# rCSL_mmcsd_001 register map
Vendor: Texas Instruments
Peripheral module from a debugger description file (folder OMAPL138_C6748).
Registers are 32-bit, access not given, reset 0x0 unless marked. A register's access mark holds for its fields unless they carry their own. Offsets are as the file gives them; lines under a group give offsets from that group; [hi:lo] are bit positions; {n}, {i} and the like mark numbered series; 'fields as' and 'values as' point back to an identical list; <NAME> marks a mode.

## MMCSD — MMC/SD Controller
0x00 MMCCTL — MMC Control Register
  [10] PERMDX rw — Endian select Enable when writing
    0=LEND (Little Endian is selected); 1=BEND (Big Endian is selected)
  [9] PERMDR rw — Endian select Enable when reading
    values as PERMDX
  [8] WIDTH1 rw — Data Bus Width1 (in only MMC mode)
  [8] WIDTH0 rw — Data Bus Width0 (in only MMC mode)
  [7:6] DATEG rw — DAT3 Edge Detection Select
  [1] CMDRST rw — CMD Logic Reset
    0=ENABLE (The CMD line portion is enabled); 1=DISABLE (The CMD line portion is disabled and in reset state)
  [0] DATRST rw — DAT Logic Reset
    0=ENABLE (The DAT line portion is enabled); 1=DISABLE (The DAT line portion is disabled and in reset state)
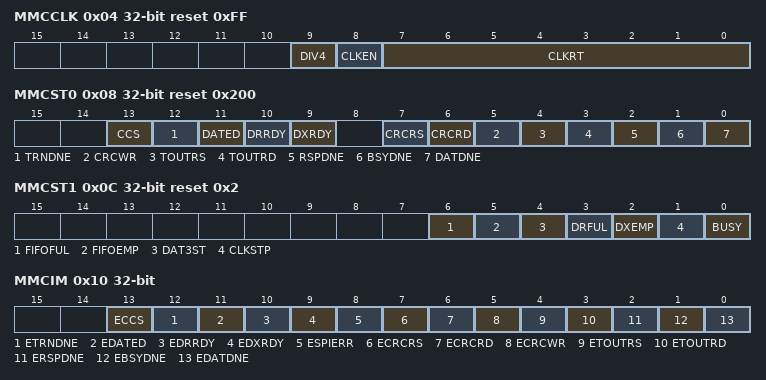
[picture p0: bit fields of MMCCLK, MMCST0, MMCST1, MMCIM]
0x04 MMCCLK reset 0xFF — MMC Memory Clock Register
  [9] DIV4 rw — DIV4 option
    0=DISABLE (DIV4 is disabled); 1=ENABLE (DIV4 is enabled)
  [8] CLKEN rw — CLK Enable
    0=DISABLE (CLK pin is disabled and fixed); 1=ENABLE (CLK pin is enabled)
  [7:0] CLKRT rw — Clock Pin Rate&#10;This indicates divider rate of the function clock&#10;MMC clock = function clock /2*(ClockRate + 1)
0x08 MMCST0 reset 0x200 — MMC Status Register 0
  [13] CCS ro — Command Completion Signal &#10;0: Command 61 is not completed&#10;1: Command 61 is completed
    0=Not_completed (Command 61 not completed); 1=Completed (Command 61 completed)
  [12] TRNDNE ro — Transfer Done&#10;0: No data transfer is done&#10;1:Data transfer of specified length is done
    0=Not_done (Data transfer not done); 1=Done (Data transfer done)
  [11] DATED ro — DAT3 Edge Detect, bit is cleared when read by CPU&#10;0: No DAT3 edge is detected&#10;1: DAT3 edge has been detected
    0=Not_detected (DAT3 Edge not detected); 1=Detected (DAT3 Edge detected)
  [10] DRRDY ro — Data Receive Ready&#10;0: MMCDRR is not ready&#10;1: MMCDRR is ready to be reading a newdata by CPU or DMA
    0=Not_ready (DRR not ready); 1=Ready (DRR ready)
  [9] DXRDY ro — Data Transmit Ready&#10;0: MMCDXR is not ready&#10;1: MMCDXR is ready to be writing a new data by CPU or DMA
    0=Not_ready (DXR not ready); 1=Ready (DXR ready)
  [7] CRCRS ro — CRC error (response)&#10;0: No CRC error is detected&#10;1: CRC error has been detected
    0=Not_detected (CRC response not detected); 1=Detected (CRC response detected)
  [6] CRCRD ro — CRC error (read data)&#10;0: No CRC error is detected&#10;1: CRC error has been detected
    0=Not_detected (CRC read data not detected); 1=Detected (CRC read data detected)
  [5] CRCWR ro — CRC error (write data)&#10;0: No CRC error is detected&#10;1: CRC error has been detected
    0=Not_detected (CRC write data not detected); 1=Detected (CRC write data detected)
  [4] TOUTRS ro — Time_Out (response)&#10;0: No time_out occurs&#10;1: Time_out has occurred during waiting response
    0=Not_occurred (Time-Out response not occurred); 1=Occurred (Time-Out response occurred)
  [3] TOUTRD ro — Time_Out (read data)&#10;0: No time_out occurs&#10;1: Time_out has occurred during waiting response
    0=Not_occurred (Time-Out read data not occurred); 1=Occurred (Time-Out read data occurred)
  [2] RSPDNE ro — Command / Response Done&#10;0: No Receiving response done&#10;1: Response successfully has received or command has sent without response
    0=Not_received (Command/Response not received); 1=Received (Command/Response received)
  [1] BSYDNE ro — Busy Done&#10;0: No busy releasing done&#10;1: Released from busy state or expected busy not detected
    0=Not_released (Busy state not released); 1=Released (Busy state released)
  [0] DATDNE ro — Data Done&#10;0: No data transfer done&#10;1: Data transfer of specified length successfully done
    values as TRNDNE
0x0C MMCST1 reset 0x2 — MMC Status Register 1
  [6] FIFOFUL ro — FIFO is full&#10;0: FIFO is not full&#10;1: FIFO is full
    0=Not_full (FIFO not full); 1=Full (FIFO full)
  [5] FIFOEMP ro — FIFO contains no data&#10;0: FIFO is not empty&#10;1: FIFO is empty
    0=Not_empty (FIFO not empty); 1=Empty (FIFO empty)
  [4] DAT3ST ro — DAT3 Status&#10;0: The status of DAT3 is L level&#10;1: The status of DAT3 is H level
    0=Low (DAT3 status low); 1=High (DAT3 status high)
  [3] DRFUL ro — DRRDY Data receive full&#10;0: MMCDRR(data receive register) is not full&#10;1: MMCDRR(data receive register) is full
    0=Not_full (DRR not full); 1=Full (DRR full)
  [2] DXEMP ro — DXRDY Data transmit empty&#10;0: MMCDXR(data transmit register) is not empty&#10;1: MMCDXR(data transmit register) is empty
    0=Not_empty (DXR not empty); 1=Empty (DXR empty)
  [1] CLKSTP ro — Clock Stop Status&#10;0:CLK is active&#10;1:CLK is held L because of no sending data during CLKEN is 0, receive shift register is full, transmit shift register is empty
    0=Low (Clock Stop status low); 1=High (Clock Stop status high)
  [0] BUSY ro — Busy&#10;0: No busy signal is detected&#10;1: Busy signal is detected after response with busy or during block write
    0=Not_detected (Busy not detected); 1=Detected (Busy detected)
0x10 MMCIM — MMC Interrupt Mask Register
  [all] fields
    0=PROHIBIT; 1=PERMIT
  [13] ECCS rw — CCS permission bit
  [12] ETRNDNE rw — TRNDNE permission bit
  [11] EDATED rw — DATED permission bit
  [10] EDRRDY rw — DRRDY permission bit
  [9] EDXRDY rw — DXRDY permission bit
  [8] ESPIERR rw — SPIERR permission bit (in SPI mode)
  [7] ECRCRS rw — CRCRS permission bit (response)
  [6] ECRCRD rw — CRCRD permission bit (read data)
  [5] ECRCWR rw — CRCWR permission bit (write data)
  [4] ETOUTRS rw — TOUTRS permission bit (response)
  [3] ETOUTRD rw — TOUTRD permission bit (read data)
  [2] ERSPDNE rw — RSPDNE permission bit
  [1] EBSYDNE rw — BSYDNE permission bit
  [0] EDATDNE rw — DATDNE permission bit
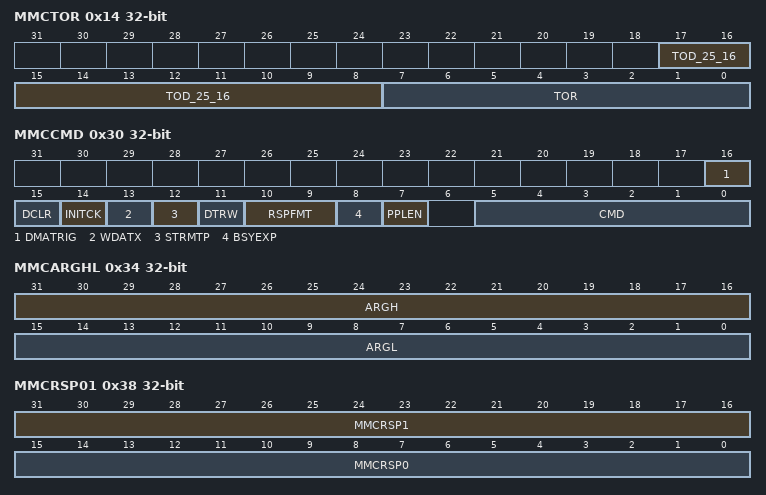
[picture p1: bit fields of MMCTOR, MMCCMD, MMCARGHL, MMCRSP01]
0x14 MMCTOR — MMC Response Time-out Register
  [17:8] TOD_25_16 rw — Upper 10 bit of Data TimeOut Register (in MMC and SPI Modes)&#10;Time_Out Count For Data Read (in MMC mode)&#10; 0x00000: no time_out&#10; 0x00001: 1 CLK clock&#10; 0x00002: 2 CLK clocks&#10; ...&#10; 0x1FFFF: 2097151 CLK clocks&#10;Time_Out Count For Data Read (in SPI mode)&#10; 0x00000: no time_out&#10; 0x00001: 1 x 8 CLK clocks&#10; 0x00002: 2 x 8 CLK clocks&#10; ...&#10; 0x1FFFFF: 2097151 x 8 CLK clocks
  [7:0] TOR rw — Time_Out Count For Response&#10;In MMC mode&#10; 0000 0000: no time_out&#10; 0000 0001: 1 CLK clock&#10; 0000 0010: 2 CLK clocks &#10; ...&#10; 1111 1111: 255 CLK clocks&#10;In SPI mode&#10; 0000 0000: no time_out&#10; 0000 0001: 1 x 8 CLK clock&#10; 0000 0010: 2 x 8 CLK clocks &#10; ...&#10; 1111 1111: 255 x 8 CLK clocks
0x18 MMCTOD — MMC Data Read Time-out Register
  [15:0] TOD_15_0 rw — Lower 16 bit of Data TimeOut Register&#10;Time_Out Count For Data Read (in MMC mode)&#10; 0x00000: no time_out&#10; 0x00001: 1 CLK clock&#10; 0x00002: 2 CLK clocks&#10; ...&#10; 0x1FFFF: 2097151 CLK clocks&#10;Time_Out Count For Data Read (in SPI mode)&#10; 0x00000: no time_out&#10; 0x00001: 1 x 8 CLK clocks&#10; 0x00002: 2 x 8 CLK clocks&#10; ...&#10; 0x1FFFFF: 2097151 x 8 CLK clocks
0x1C MMCBLEN reset 0x200 — MMC Block Length Register
  [11:0] BLEN rw — Block Length&#10;Specifies the byte count of a data block. Value 0x000 is prohibited
0x20 MMCNBLK — MMC Number of Blocks Register
  [15:0] NBLK rw — Number of Blocks&#10;Specifies the total number of blocks to be transferred.The value 0x0000 means infinite blocks
0x24 MMCNBLC reset 0xFFFF — MMC Number of Blocks Counter
  [15:0] NBLC rw — MMCNBLC is used in order to test the counter which operates with the value of MMCNBLK in a factory test or a chip evaluation&#10;Reading is possible in order to check the number of blocks to be transferred But Writing to this register is prohibited by User
0x28 MMCDRR rw — MMC Data Receive Register
  [31:0] DRR — This register is used for reading of receive data from card when block read&#10;&#10;Register expects little endian formatting
0x2C MMCDXR rw — MMC Data Transmit Register
  [31:0] DXR — This register is used for writing of transmit data to card when block write&#10;&#10;Register expects little endian formatting
0x30 MMCCMD — MMC Command Register
  [16] DMATRIG rw — DMA transfer event generation enable
    0=NO (Do not generate DMA transfer event); 1=YES (Generate DMA transfer event (mmcsd_dma_xready_o))
  [15] DCLR rw — Data Receive/Transmit Clear
    0=NO (No clear); 1=CLEAR
  [14] INITCK rw — Initialize Clock&#10;Before sending the command (specified in CMD), 80 cycles of dummy clock will be inserted. This is required for resetting a card after power_on
    0=NO (No initialization clock); 1=INIT (Initialization clock insertion)
  [13] WDATX rw — With Data
    0=NO (No data transfer); 1=DATA (With data transfer)
  [12] STRMTP rw — Stream Transfer
    0=BLOCK (Block data transfer); 1=STREAM (Stream data transfer); 0=NO (When WDATX = 0)
  [11] DTRW rw — Write
    0=READ (Data read); 1=WRITE (Data write); 0=NO (When WDATX = 0)
  [10:9] RSPFMT rw — Response Format&#10;00:&#10;01: R1/R4/R5/R6 (48_bit length)&#10;10: R2 (136_bit length)&#10;11: R3 (48_bit length, without CRC)
  [8] BSYEXP rw — Busy Expected
    0=NO (No busy signal expected); 1=BUSY (Busy signal expected or in case of transfer abort)
  [7] PPLEN rw — Push Pull Enable
    0=OD (Push Pull Driver of CMD line is disable (Open drain)); 1=PP (Push Pull Driver of CMD line is enable)
  [5:0] CMD rw — Command Index&#10;The command to be sent to the CMD line
0x34 MMCARGHL rw — MMC Argument Register
  [31:16] ARGH — MSB of Argument Register&#10;MMCARGHL is used for specifying the arguments to be sent with the command specified by MMCCMD. Writing to MMCCMD cause start event of sending operation, that is, MMCARG has to be set before writing to MMCCMD. The content of this register will be kept after transfer to the shift register. However, modification to MMCARG is not allowed during sending operation
  [15:0] ARGL — LSB of Argument Register
0x38 MMCRSP01 rw — MMC Response Register 0 and 1
  [31:16] MMCRSP1 — Response Register 1
  [15:0] MMCRSP0 — Response Register 0
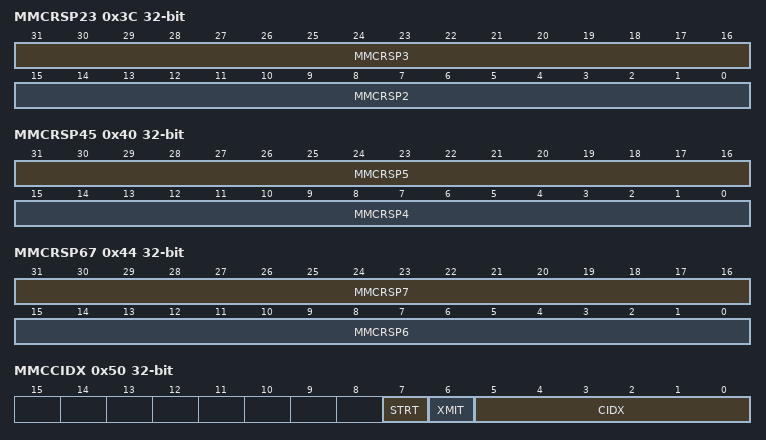
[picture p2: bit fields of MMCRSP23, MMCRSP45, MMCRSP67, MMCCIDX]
0x3C MMCRSP23 rw — MMC Response Register 2 and 3
  [31:16] MMCRSP3 — Response Register 3
  [15:0] MMCRSP2 — Response Register 2
0x40 MMCRSP45 rw — MMC Response Register 4 and 5
  [31:16] MMCRSP5 — Response Register 5
  [15:0] MMCRSP4 — Response Register 4
0x44 MMCRSP67 rw — MMC Response Register 6 and 7
  [31:16] MMCRSP7 — Response Register 7
  [15:0] MMCRSP6 — Response Register 6
0x48 MMCDRSP — MMC Data Response Register
  [7:0] DRSP rw — Data Response&#10;During a write operation, the CRC status token is stored in this register
0x50 MMCCIDX — MMC Command Index Register
  [7] STRT rw — Start bit
  [6] XMIT rw — Transmission bit
  [5:0] CIDX rw — Command Index&#10;Command index, is stored when it is received in MMC mode
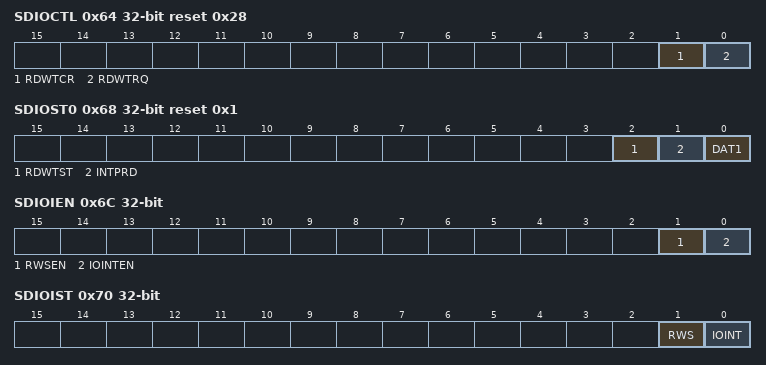
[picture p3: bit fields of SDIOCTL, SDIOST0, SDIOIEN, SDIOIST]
0x64 SDIOCTL reset 0x28 — SDIO Control Register
  [1] RDWTCR rw — Read Wait enable for CRC error If this bit is set, Read Wait operation automatically starts in case a CRC error is detected during multiple block read access, and while it's not the last block to be transferred. In this case, RDWTRQ (Read Wait request) is automatically set. To end the Read Wait operation, write '0' to RDWTRQ. (No need to clear RDWTCR)
    0=DISABLE (No read wait on CRC error); 1=ENABLE (Automatically start read wait on CRC error)
  [0] RDWTRQ rw — Read Wait request 0: End Read Wait operation and release DAT[2] 1: Set a Read Wait request. If this bit is set, Read Wait operation starts 2 clocks after the end of the read data block. MMCIF asserts low level on DAT[2] until this bit is cleared
    0=DISABLE (End read wait request); 1=ENABLE (Enable read wait request)
0x68 SDIOST0 reset 0x1 — SDIO Status Register 0
  [2] RDWTST ro — Read Wait status RDWTST becomes '1' during Read Wait operation
    0=CLEAR (No Read Wait Status); 1=SET (Read Wait Status set)
  [1] INTPRD ro — Interrupt period INTPRD becomes '1' during Interrupt period
    0=CLEAR (No Interrupt period); 1=SET (Interupt period set)
  [0] DAT1 ro — DAT[1] status DAT[1] can be monitored through this bit
    0=CLEAR (Dat[1] is low); 1=SET (Dat[1] is high)
0x6C SDIOIEN — SDIO Interrupt Enable Register
  [1] RWSEN rw — Read Wait interrupt enable
    0=DISABLE (Read Wait interrupt disable); 1=ENABLE (Read Wait interrupt enable)
  [0] IOINTEN rw — SDIO card interrupt enable
    0=DISABLE (SDIO card interrupt disable); 1=ENABLE (SDIO card interrupt enable)
0x70 SDIOIST — SDIO Interrupt Status Register
  [1] RWS rw — Read Wait interrupt status 0: Not interrupted 1: Interrupted This bit is set to '1' when Read Wait operation starts and Read Wait interrupt is enabled. To clear this bit, write '1'
    0=CLEAR (No Read Wait Interrupt); 1=SET (Read Wait Interrupt Status set)
  [0] IOINT rw — SDIO card interrupt status 0: Not interrupted 1: Interrupted This bit is set to '1' if the SDIO card interrupt is detected and card interrupt is enabled. To clear this bit, write '1' after the interrupt on the DAT[1] line is removed
    0=CLEAR (No SDIO card interrupt); 1=SET (SDIO card interrupt set)
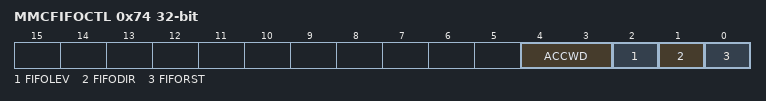
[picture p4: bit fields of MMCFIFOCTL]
0x74 MMCFIFOCTL — FIFO Control Register
  [4:3] ACCWD rw — Access Width (used by FIFO control to determine full/empty flag)
  [2] FIFOLEV rw — Sets the threshold level which is used to determine when DMA request and FIFO threshold interrupt are triggered
    0=256BIT (DMA Request every 256 bit sent/received); 1=512BIT (DMA Request every 512 bit sent/received)
  [1] FIFODIR rw — Determines if the FIFO is being written to or read from
    0=READ (Read from FIFO); 1=WRITE (Write to FIFO)
  [0] FIFORST rw — Reset the internal state of the FIFO
    1=RESET (Reset FIFO)
